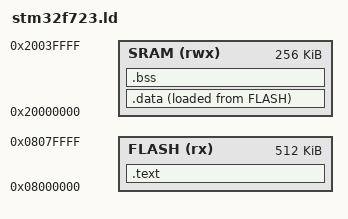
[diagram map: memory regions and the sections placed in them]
MEMORY
{
    FLASH (rx)  : ORIGIN = 0x08000000, LENGTH = 512K
    SRAM  (rwx) : ORIGIN = 0x20000000, LENGTH = 256K
}

SECTIONS
{
    .text : {
        KEEP(*(.vectors))
        *(.text*)
        *(.rodata*)
    } > FLASH

    .data : {
        _data_start = .;
        *(.data*)
        _data_end = .;
    } > SRAM AT > FLASH

    _data_load = LOADADDR(.data);

    .bss : {
        _bss_start = .;
        *(.bss*)
        *(COMMON)
        _bss_end = .;
    } > SRAM

    _stack_top = ORIGIN(SRAM) + LENGTH(SRAM);
}
